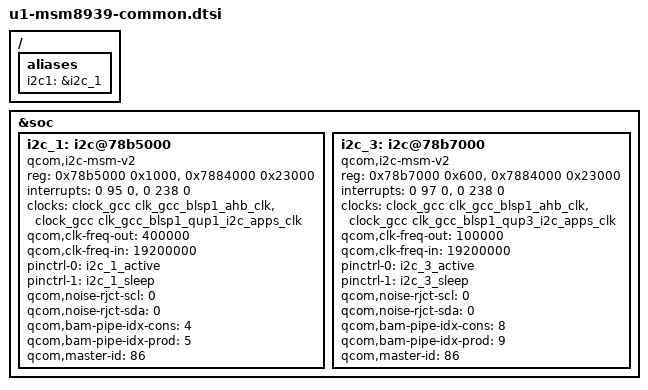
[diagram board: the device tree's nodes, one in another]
/* Copyright (c) 2014-2015, The Linux Foundation. All rights reserved.
 *
 * This program is free software; you can redistribute it and/or modify
 * it under the terms of the GNU General Public License version 2 and
 * only version 2 as published by the Free Software Foundation.
 *
 * This program is distributed in the hope that it will be useful,
 * but WITHOUT ANY WARRANTY; without even the implied warranty of
 * MERCHANTABILITY or FITNESS FOR A PARTICULAR PURPOSE.  See the
 * GNU General Public License for more details.
 */

/ {
	aliases {
		i2c1 = &i2c_1;
	};
};

&soc {
	i2c_1: i2c@78b5000 { /* BLSP1 QUP1 */
		compatible = "qcom,i2c-msm-v2";
	#address-cells=<1>;
	#size-cells=<0>;
		reg-names = "qup_phys_addr", "bam_phys_addr";
		reg = <0x78b5000 0x1000>,
				<0x7884000 0x23000>;
		interrupt-names = "qup_irq", "bam_irq";
		interrupts = <0 95 0>, <0 238 0>;
		clocks = <&clock_gcc clk_gcc_blsp1_ahb_clk>,
				<&clock_gcc clk_gcc_blsp1_qup1_i2c_apps_clk>;
		clock-names = "iface_clk", "core_clk";
		qcom,clk-freq-out = <400000>;
		qcom,clk-freq-in  = <19200000>;
		pinctrl-names = "i2c_active", "i2c_sleep";
		pinctrl-0 = <&i2c_1_active>;
		pinctrl-1 = <&i2c_1_sleep>;
		qcom,noise-rjct-scl = <0>;
		qcom,noise-rjct-sda = <0>;
		qcom,bam-pipe-idx-cons = <4>;
		qcom,bam-pipe-idx-prod = <5>;
		qcom,master-id = <86>;
	};

	i2c_3: i2c@78b7000 { /* BLSP1 QUP3 */
		compatible = "qcom,i2c-msm-v2";
		#address-cells = <1>;
		#size-cells = <0>;
		reg-names = "qup_phys_addr", "bam_phys_addr";
		reg = <0x78b7000 0x600>,
		      <0x7884000 0x23000>;
		interrupt-names = "qup_irq", "bam_irq";
		interrupts = <0 97 0>, <0 238 0>;
		clocks = <&clock_gcc clk_gcc_blsp1_ahb_clk>,
			 <&clock_gcc clk_gcc_blsp1_qup3_i2c_apps_clk>;
		clock-names = "iface_clk", "core_clk";
		qcom,clk-freq-out = <100000>;
		qcom,clk-freq-in  = <19200000>;
		pinctrl-names = "i2c_active", "i2c_sleep";
		pinctrl-0 = <&i2c_3_active>;
		pinctrl-1 = <&i2c_3_sleep>;
		qcom,noise-rjct-scl = <0>;
		qcom,noise-rjct-sda = <0>;
		qcom,bam-pipe-idx-cons = <8>;
		qcom,bam-pipe-idx-prod = <9>;
		qcom,master-id = <86>;
	};
/*	spi_0: spi@78b7000 {
		compatible = "qcom,spi-qup-v2";
		#address-cells = <1>;
		#size-cells = <0>;
		reg-names = "spi_physical", "spi_bam_physical";
		reg = <0x78b7000 0x600>,
			<0x7884000 0x23000>;
		interrupt-names = "spi_irq", "spi_bam_irq";
		interrupts = <0 97 0>, <0 238 0>;
		spi-max-frequency = <19200000>;
		pinctrl-names = "spi_default", "spi_sleep";
		pinctrl-0 = <&spi0_default &spi0_cs0_active>;
		pinctrl-1 = <&spi0_sleep &spi0_cs0_sleep>;
		clocks = <&clock_gcc clk_gcc_blsp1_ahb_clk>,
			<&clock_gcc clk_gcc_blsp1_qup3_spi_apps_clk>;
		clock-names = "iface_clk", "core_clk";
		qcom,infinite-mode = <0>;
		qcom,use-bam;
		qcom,use-pinctrl;
		qcom,ver-reg-exists;
		qcom,bam-consumer-pipe-index = <8>;
		qcom,bam-producer-pipe-index = <9>;
		qcom,master-id = <86>;
		};*/
};

